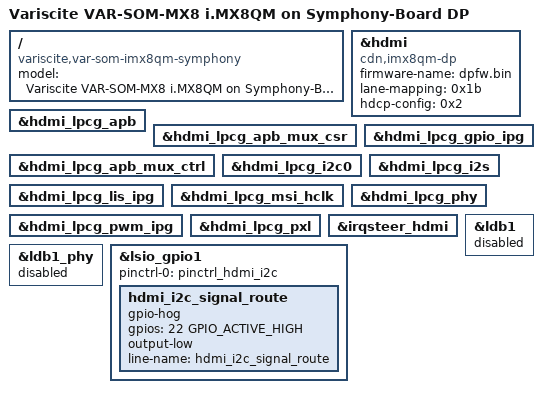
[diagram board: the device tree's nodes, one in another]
// SPDX-License-Identifier: (GPL-2.0+ OR MIT)
/*       
 * Copyright (C) 2026 Variscite Ltd. - https://www.variscite.com/
 *
 */

#include "imx8qm-var-som-symphony.dts"

/ {
	model = "Variscite VAR-SOM-MX8 i.MX8QM on Symphony-Board DP";
	compatible = "variscite,var-som-imx8qm-symphony",
		     "variscite,var-som-imx8qm", "fsl,imx8qm";
};

&hdmi {
	compatible = "cdn,imx8qm-dp";
	firmware-name = "dpfw.bin";
	lane-mapping = <0x1b>;
	hdcp-config = <0x2>;
	status = "okay";
};

&hdmi_lpcg_apb {
	status = "okay";
};

&hdmi_lpcg_apb_mux_csr {
	status = "okay";
};

&hdmi_lpcg_apb_mux_ctrl {
	status = "okay";
};

&hdmi_lpcg_gpio_ipg {
	status = "okay";
};

&hdmi_lpcg_i2c0 {
	status = "okay";
};

&hdmi_lpcg_i2s {
	status = "okay";
};

&hdmi_lpcg_lis_ipg {
	status = "okay";
};

&hdmi_lpcg_msi_hclk {
	status = "okay";
};

&hdmi_lpcg_phy {
	status = "okay";
};

&hdmi_lpcg_pwm_ipg {
	status = "okay";
};

&hdmi_lpcg_pxl {
	status = "okay";
};

&irqsteer_hdmi {
	status = "okay";
};

&ldb1 {
	status = "disabled";
};

&ldb1_phy {
	status = "disabled";
};

&lsio_gpio1 {
	pinctrl-names = "default";
	pinctrl-0 = <&pinctrl_hdmi_i2c>;

	hdmi_i2c_signal_route {
		gpio-hog;
		gpios = <22 GPIO_ACTIVE_HIGH>;
		output-low;
		line-name = "hdmi_i2c_signal_route";
	};
};
